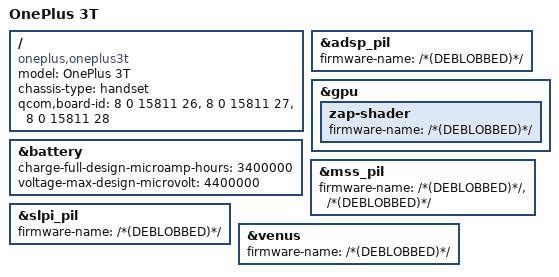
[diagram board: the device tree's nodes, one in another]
// SPDX-License-Identifier: GPL-2.0-only
/*
 * Copyright (c) 2022, Harry Austen <hpausten@protonmail.com>
 */

/dts-v1/;

#include "msm8996-oneplus-common.dtsi"

/ {
	model = "OnePlus 3T";
	compatible = "oneplus,oneplus3t", "qcom,msm8996";
	chassis-type = "handset";
	qcom,board-id = <8 0 15811 26>,
			<8 0 15811 27>,
			<8 0 15811 28>;
};

&adsp_pil {
	firmware-name = "/*(DEBLOBBED)*/";
};

&battery {
	charge-full-design-microamp-hours = <3400000>;
	voltage-max-design-microvolt = <4400000>;
};

&gpu {
	zap-shader {
		firmware-name = "/*(DEBLOBBED)*/";
	};
};

&mss_pil {
	firmware-name = "/*(DEBLOBBED)*/",
			"/*(DEBLOBBED)*/";
};

&slpi_pil {
	firmware-name = "/*(DEBLOBBED)*/";
};

&venus {
	firmware-name = "/*(DEBLOBBED)*/";
};
